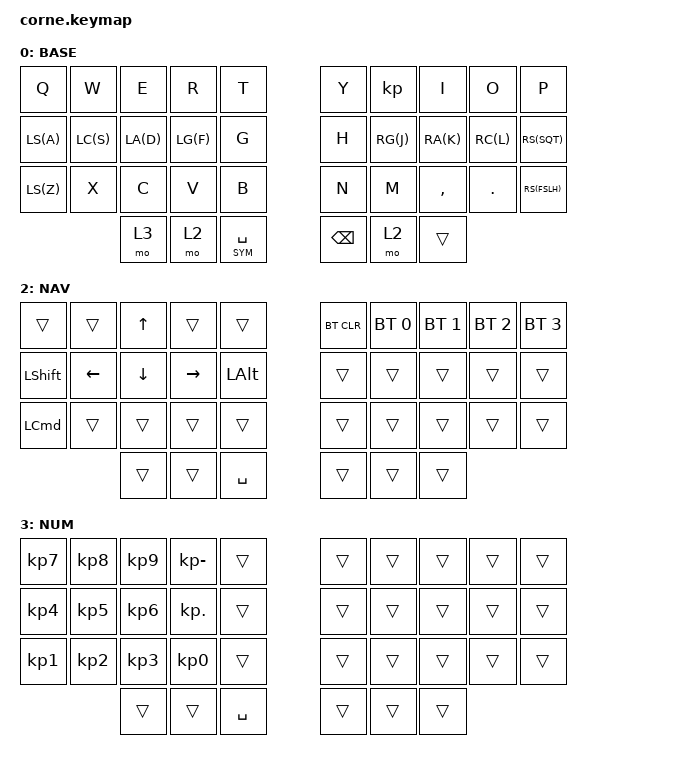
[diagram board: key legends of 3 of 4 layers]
/*
 * Copyright (c) 2020 The ZMK Contributors
 *
 * SPDX-License-Identifier: MIT
 */

#include <behaviors.dtsi>
#include <dt-bindings/zmk/keys.h>
#include <dt-bindings/zmk/bt.h>

#define BAS 0
#define SYM 1
#define NAV 2
#define NUM 3


/*                KEY POSITIONS

  ╭────────────────────╮ ╭────────────────────╮
  │  0   1   2   3   4 │ │  5   6   7   8   9 │
  │ 10  11  12  13  14 │ │ 15  16  17  18  19 │
  │ 20  21  22  23  24 │ │ 25  26  27  28  29 │
  ╰───────╮ 30  31  32 │ │ 28  29  30 ╭───────╯
          ╰────────────╯ ╰────────────╯            */

/ {
    combos {
        compatible = "zmk,combos";
        combo_esc {
            timeout-ms = <50>;
            key-positions = <0 1>;
            bindings = <&kp ESC>;
        };
        combo_tab {
            timeout-ms = <50>;
            key-positions = <12 13>;
            bindings = <&kp TAB>;
        };
        combo_enterleft {
            timeout-ms = <50>;
            key-positions = <11 12>;
            bindings = <&kp ENTER>;
        };
        combo_enterright {
            timeout-ms = <50>;
            key-positions = <17 18>;
            bindings = <&kp ENTER>;
        };
        combo_caps {
            timeout-ms = <50>;
            key-positions = <13 16>;
            bindings = <&kp CAPS>;
        };

    chosen {
      zmk,matrix_transform = &five_column_transform;
    };

    behaviors {
        as: auto_shift {
            compatible = "zmk,behavior-hold-tap";
            #binding-cells = <2>;
            tapping_term_ms = <200>;
            quick_tap_ms = <0>;
            flavor = "tap-preferred";
            bindings = <&kp>, <&kp>;
        };
    };
        keymap {
                compatible = "zmk,keymap";

                BASE {
// 
// |  Q  |  W  |  E  |  R  |  T  |      |  Y  |  U  |  I  |  O  |  P  |
// |  A  |  S  |  D  |  F  |  G  |      |  H  |  J  |  K  |  L  |  '  | 
// |  Z  |  X  |  C  |  V  |  B  |      |  N  |  M  |  ,  |  .  |  ?  |
//             | NUM | NAV | SPC |      | BSP | SYM |     |
                        display-name = "BASE";
                        bindings = <
   &kp Q  &kp W  &kp E  &kp R  &kp T           &kp Y     &kp      &kp I      &kp O    &kp P
   LS(A)  LC(S)  LA(D)  LG(F)  &kp G           &kp H     RG(J)    RA(K)      RC(L)    RS(SQT)
   LS(Z)  &kp X  &kp C  &kp V  &kp B           &kp N     &kp M    &kp COMMA  &kp DOT  RS(FSLH)
                 &mo 3  &mo 2  &lt SYM SPACE   &kp BSPC  &mo 2    &trans
                        >;
                };

                SYM {
// 
// | 1!  | 2@  | 3#  | 4$  | 5%  |      | 6^  | 7&  | 8*  | 9(  | 0)  |
// | 6^  | 7&  | 8*  | 9(  | 0)  |      |     |     | =+  | -_  | ;:  |
// | |\  | `~  |     | VDN | VUP |      |     |     |     |     |     |
//             |     |     |  ▽  |      | DEL |  ▽  |     |
                        display-name = "SYM";
                        bindings = <
   &as N1     &as N2      &as N3    &as N4         &as N5         &as N6    &as N7   &as N8    &as N9    &as N0
   &as N6     &as N7      &as N8    &as N9         &as N0         &trans    &trans   &as EQUAL &as MINUS &as SEMI
   &as MINUS  &as GRAVE   &trans    &kp C_VOL_DN   &kp C_VOL_UP   &trans    &trans   &trans    &trans
                          &trans    &trans         &trans         &kp DEL   &trans   &trans
                       >;
                };

                NAV {
// 
// |     |     | UP  |     |     |      | BTCLR | BT1 | BT2 | BT3 | BT4 |
// | SFT | LFT | DWN | RGT | ALT |      |       |     |     |     |     |
// | CMD |     |     |     |     |      |       |     |     |     |     |
//             |     |  ▽  | SPC |      |       |     |     |
                        display-name = "NAV";
                        bindings = <
   &trans      &trans   &kp UP   &trans    &trans       &bt BT_CLR  &bt BT_SEL 0  &bt BT_SEL 1  &bt BT_SEL 2  &bt BT_SEL 3
   &kp LSHIFT  &kp LEFT &kp DOWN &kp RIGHT &kp LALT     &trans      &trans        &trans        &trans        &trans 
   &kp LCMD    &trans   &trans   &trans    &trans       &trans      &trans        &trans        &trans        &trans 
                        &trans   &trans    &kp SPACE    &trans      &trans        &trans
                       >;
                };

                NUM {
// 
// |  7  |  8  |  9  |  -  |     |      |     |     |     |     |     |
// |  4  |  5  |  6  |  .  |     |      |     |     |     |     |     |
// |  1  |  2  |  3  |  0  |     |      |     |     |     |     |     |
//             |  ▽  |     | SPC |      |     |     |     |
                        display-name = "NUM";
                        bindings = <
   &kp KP_N7  &kp KP_N8  &kp KP_N9  &kp KP_MINUS &trans        &trans  &trans  &trans  &trans  &trans
   &kp KP_N4  &kp KP_N5  &kp KP_N6  &kp KP_DOT   &trans        &trans  &trans  &trans  &trans  &trans 
   &kp KP_N1  &kp KP_N2  &kp KP_N3  &kp KP_N0    &trans        &trans  &trans  &trans  &trans  &trans 
                         &trans     &trans       &kp SPACE     &trans  &trans  &trans
                        >;
                };
        };
};
 
